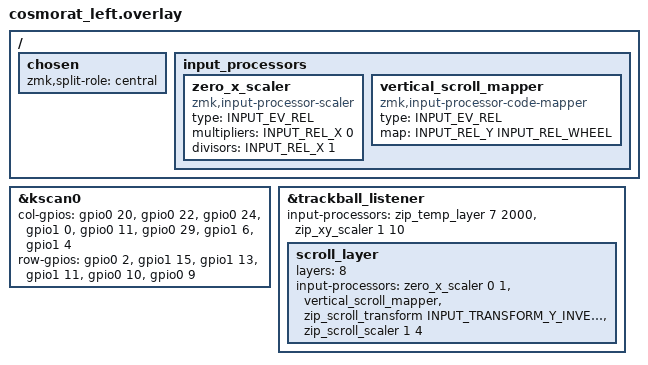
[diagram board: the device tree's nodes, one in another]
#include "cosmorat.dtsi"
#include <input/processors.dtsi>
#include <dt-bindings/zmk/input_transform.h>
#include <zephyr/dt-bindings/input/input-event-codes.h>

/ {
    chosen {
        zmk,split-role = "central";
    };

    input_processors {
        zero_x_scaler: zero_x_scaler {
            compatible = "zmk,input-processor-scaler";
            #input-processor-cells = <2>;
            type = <INPUT_EV_REL>;
            multipliers = <INPUT_REL_X 0>;
            divisors = <INPUT_REL_X 1>;
        };
        
        vertical_scroll_mapper: vertical_scroll_mapper {
            compatible = "zmk,input-processor-code-mapper";
            #input-processor-cells = <0>;
            type = <INPUT_EV_REL>;
            map = <INPUT_REL_Y INPUT_REL_WHEEL>;
        };
    };
};

&kscan0 {
    col-gpios
        = <&gpio0 20 GPIO_ACTIVE_HIGH>
        , <&gpio0 22 GPIO_ACTIVE_HIGH>
        , <&gpio0 24 GPIO_ACTIVE_HIGH>
        , <&gpio1 0 GPIO_ACTIVE_HIGH>
        , <&gpio0 11 GPIO_ACTIVE_HIGH>
        , <&gpio0 29 GPIO_ACTIVE_HIGH>
        , <&gpio1 6 GPIO_ACTIVE_HIGH>
        , <&gpio1 4 GPIO_ACTIVE_HIGH>
        ;
        
    row-gpios
        = <&gpio0 2 (GPIO_ACTIVE_HIGH | GPIO_PULL_DOWN)>
        , <&gpio1 15 (GPIO_ACTIVE_HIGH | GPIO_PULL_DOWN)>
        , <&gpio1 13 (GPIO_ACTIVE_HIGH | GPIO_PULL_DOWN)>
        , <&gpio1 11 (GPIO_ACTIVE_HIGH | GPIO_PULL_DOWN)>
        , <&gpio0 10 (GPIO_ACTIVE_HIGH | GPIO_PULL_DOWN)>
        , <&gpio0 9 (GPIO_ACTIVE_HIGH | GPIO_PULL_DOWN)>
        ;
};

&trackball_listener {
    status = "okay";
    input-processors = <&zip_temp_layer 7 2000 &zip_xy_scaler 1 10>;

    scroll_layer {
        layers = <8>;
        input-processors = <&zero_x_scaler 0 1 &vertical_scroll_mapper &zip_scroll_transform INPUT_TRANSFORM_Y_INVERT &zip_scroll_scaler 1 4>;
    };
};
